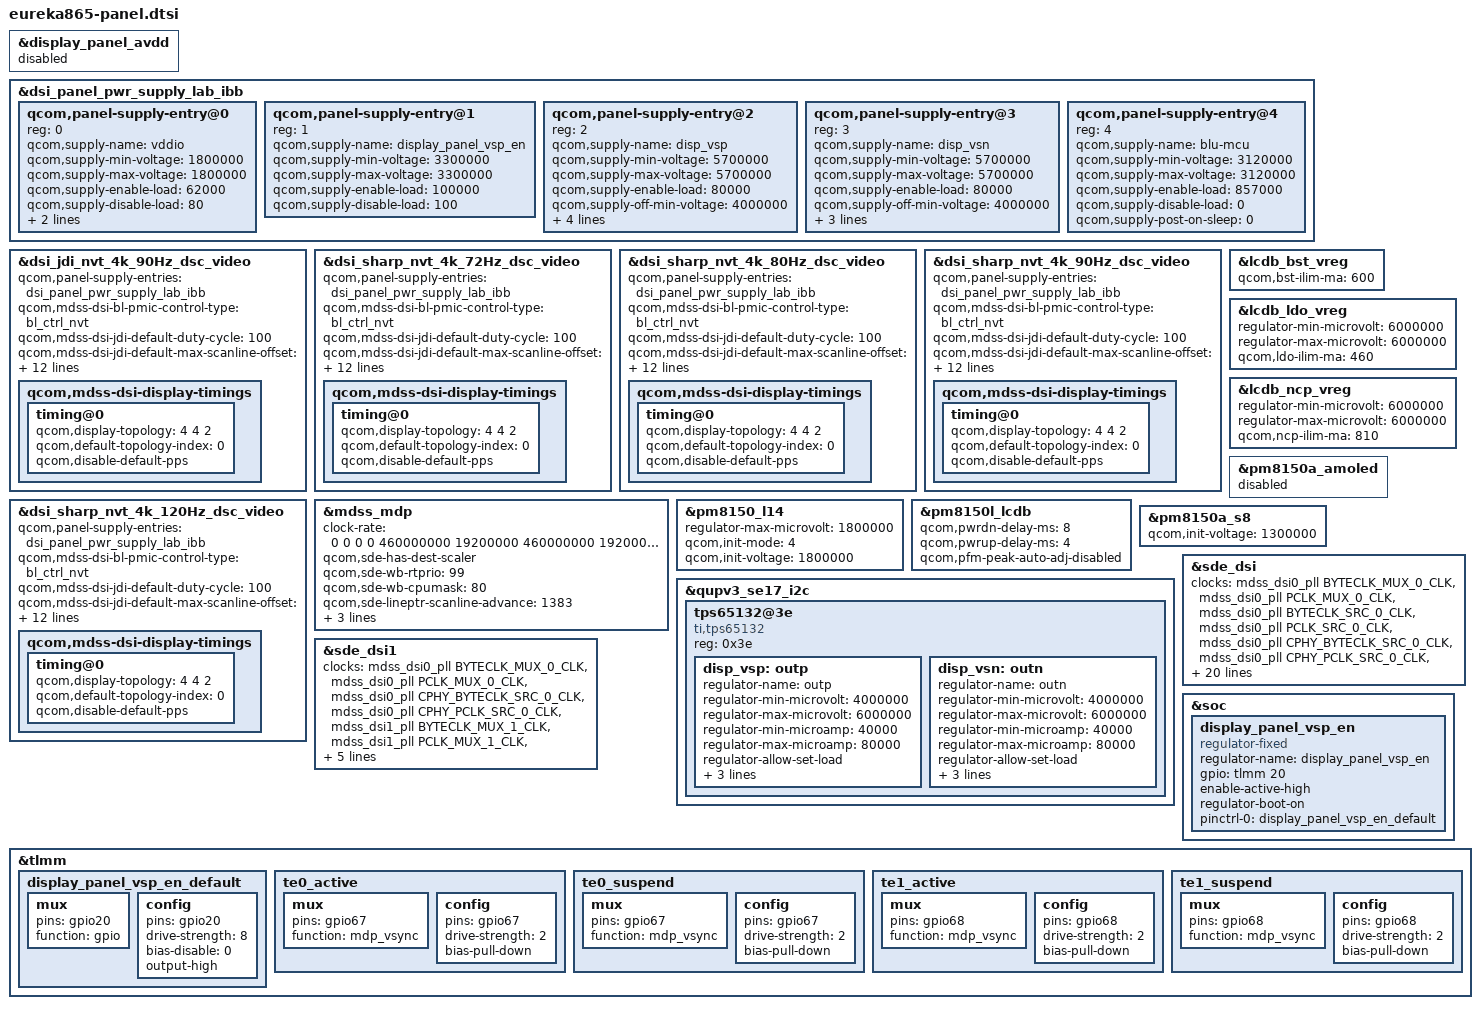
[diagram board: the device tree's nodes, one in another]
// SPDX-License-Identifier: GPL-2.0

#include "eureka865-dsi-panel-sharp-nvt-dsc-4k-72hz-video.dtsi"
#include "eureka865-dsi-panel-sharp-nvt-dsc-4k-80hz-video.dtsi"
#include "eureka865-dsi-panel-sharp-nvt-dsc-4k-90hz-video.dtsi"
#include "eureka865-dsi-panel-sharp-nvt-dsc-4k-120hz-video.dtsi"
#include "eureka865-dsi-panel-jdi-nvt-dsc-4k-90hz-video.dtsi"

&display_panel_avdd {
	status = "disabled";
};

&dsi_panel_pwr_supply_lab_ibb {
	qcom,panel-supply-entry@0 {
		reg = <0>;
		qcom,supply-name = "vddio";
		qcom,supply-min-voltage = <1800000>;
		qcom,supply-max-voltage = <1800000>;
		qcom,supply-enable-load = <62000>;
		qcom,supply-disable-load = <80>;
		qcom,supply-post-on-sleep = <20>;
		qcom,supply-pre-off-sleep = <15>;
	};

	qcom,panel-supply-entry@1 {
		reg = <1>;
		qcom,supply-name = "display_panel_vsp_en";
		qcom,supply-min-voltage = <3300000>;
		qcom,supply-max-voltage = <3300000>;
		qcom,supply-enable-load = <100000>;
		qcom,supply-disable-load = <100>;
	};

	qcom,panel-supply-entry@2 {
		reg = <2>;
		qcom,supply-name = "disp_vsp";
		qcom,supply-min-voltage = <5700000>;
		qcom,supply-max-voltage = <5700000>;
		qcom,supply-enable-load = <80000>;
		qcom,supply-off-min-voltage = <4000000>;
		qcom,supply-disable-load = <0>;
		qcom,supply-post-on-sleep = <20>;
		qcom,supply-pre-on-sleep = <10>;
		qcom,supply-pre-off-sleep = <10>;
	};

	qcom,panel-supply-entry@3 {
		reg = <3>;
		qcom,supply-name = "disp_vsn";
		qcom,supply-min-voltage = <5700000>;
		qcom,supply-max-voltage = <5700000>;
		qcom,supply-enable-load = <80000>;
		qcom,supply-off-min-voltage = <4000000>;
		qcom,supply-disable-load = <0>;
		qcom,supply-post-on-sleep = <0>;
		qcom,supply-pre-on-sleep = <10>;
	};

	qcom,panel-supply-entry@4 {
		reg = <4>;
		qcom,supply-name = "blu-mcu";
		qcom,supply-min-voltage = <3120000>;
		qcom,supply-max-voltage = <3120000>;
		qcom,supply-enable-load = <857000>;
		qcom,supply-disable-load = <0>;
		qcom,supply-post-on-sleep = <0>;
	};
};

&dsi_jdi_nvt_4k_90Hz_dsc_video {
	qcom,panel-supply-entries = <&dsi_panel_pwr_supply_lab_ibb>;
	qcom,mdss-dsi-bl-pmic-control-type = "bl_ctrl_nvt";
	qcom,mdss-dsi-jdi-default-duty-cycle = <100>; /* 10% duty */
	qcom,mdss-dsi-jdi-default-max-scanline-offset = <2036>;
	qcom,mdss-dsi-bl-min-level = <800>;
	qcom,mdss-dsi-bl-max-level = <1200>;
	qcom,platform-reset-gpio = <&tlmm 91 0>;
	qcom,panel-sec-reset-gpio = <&tlmm 49 0>;
	qcom,mdss-dsi-reset-off-delay = <30>;
	qcom,mdss-dsi-t-clk-post = <0x0F>;
	qcom,mdss-dsi-t-clk-pre = <0x1F>;
	qcom,mdss-dsi-qsync-min-refresh-rate = <60>;
	qcom,dsi-select-clocks = "mux_byte_clk0", "mux_pixel_clk0",
				"cphy_byte_clk0", "cphy_pixel_clk0";
	qcom,mdss-dsi-display-timings {
		timing@0{
			qcom,display-topology = <4 4 2>;
			qcom,default-topology-index = <0>;
			qcom,disable-default-pps;
		};
	};
};

&dsi_sharp_nvt_4k_72Hz_dsc_video {
	qcom,panel-supply-entries = <&dsi_panel_pwr_supply_lab_ibb>;
	qcom,mdss-dsi-bl-pmic-control-type = "bl_ctrl_nvt";
	qcom,mdss-dsi-jdi-default-duty-cycle = <100>; /* 10% duty */
	qcom,mdss-dsi-jdi-default-max-scanline-offset = <2036>;
	qcom,mdss-dsi-bl-min-level = <800>;
	qcom,mdss-dsi-bl-max-level = <1200>;
	qcom,platform-reset-gpio = <&tlmm 91 0>;
	qcom,panel-sec-reset-gpio = <&tlmm 49 0>;
	qcom,mdss-dsi-reset-off-delay = <30>;
	qcom,mdss-dsi-t-clk-post = <0x0F>;
	qcom,mdss-dsi-t-clk-pre = <0x1F>;
	qcom,mdss-dsi-qsync-min-refresh-rate = <60>;
	qcom,dsi-select-clocks = "mux_byte_clk0", "mux_pixel_clk0",
				"cphy_byte_clk0", "cphy_pixel_clk0";
	qcom,mdss-dsi-display-timings {
		timing@0{
			qcom,display-topology = <4 4 2>;
			qcom,default-topology-index = <0>;
			qcom,disable-default-pps;
		};
	};
};


&dsi_sharp_nvt_4k_80Hz_dsc_video {
	qcom,panel-supply-entries = <&dsi_panel_pwr_supply_lab_ibb>;
	qcom,mdss-dsi-bl-pmic-control-type = "bl_ctrl_nvt";
	qcom,mdss-dsi-jdi-default-duty-cycle = <100>; /* 10% duty */
	qcom,mdss-dsi-jdi-default-max-scanline-offset = <2036>;
	qcom,mdss-dsi-bl-min-level = <800>;
	qcom,mdss-dsi-bl-max-level = <1200>;
	qcom,platform-reset-gpio = <&tlmm 91 0>;
	qcom,panel-sec-reset-gpio = <&tlmm 49 0>;
	qcom,mdss-dsi-reset-off-delay = <30>;
	qcom,mdss-dsi-t-clk-post = <0x0F>;
	qcom,mdss-dsi-t-clk-pre = <0x1F>;
	qcom,mdss-dsi-qsync-min-refresh-rate = <60>;
	qcom,dsi-select-clocks = "mux_byte_clk0", "mux_pixel_clk0",
				"cphy_byte_clk0", "cphy_pixel_clk0";
	qcom,mdss-dsi-display-timings {
		timing@0{
			qcom,display-topology = <4 4 2>;
			qcom,default-topology-index = <0>;
			qcom,disable-default-pps;
		};
	};
};

&dsi_sharp_nvt_4k_90Hz_dsc_video {
	qcom,panel-supply-entries = <&dsi_panel_pwr_supply_lab_ibb>;
	qcom,mdss-dsi-bl-pmic-control-type = "bl_ctrl_nvt";
	qcom,mdss-dsi-jdi-default-duty-cycle = <100>; /* 10% duty */
	qcom,mdss-dsi-jdi-default-max-scanline-offset = <2036>;
	qcom,mdss-dsi-bl-min-level = <800>;
	qcom,mdss-dsi-bl-max-level = <1200>;
	qcom,platform-reset-gpio = <&tlmm 91 0>;
	qcom,panel-sec-reset-gpio = <&tlmm 49 0>;
	qcom,mdss-dsi-reset-off-delay = <30>;
	qcom,mdss-dsi-t-clk-post = <0x0F>;
	qcom,mdss-dsi-t-clk-pre = <0x1F>;
	qcom,mdss-dsi-qsync-min-refresh-rate = <60>;
	qcom,dsi-select-clocks = "mux_byte_clk0", "mux_pixel_clk0",
				"cphy_byte_clk0", "cphy_pixel_clk0";
	qcom,mdss-dsi-display-timings {
		timing@0{
			qcom,display-topology = <4 4 2>;
			qcom,default-topology-index = <0>;
			qcom,disable-default-pps;
		};
	};
};

&dsi_sharp_nvt_4k_120Hz_dsc_video {
	qcom,panel-supply-entries = <&dsi_panel_pwr_supply_lab_ibb>;
	qcom,mdss-dsi-bl-pmic-control-type = "bl_ctrl_nvt";
	qcom,mdss-dsi-jdi-default-duty-cycle = <100>; /* 10% duty */
	qcom,mdss-dsi-jdi-default-max-scanline-offset = <2036>;
	qcom,mdss-dsi-bl-min-level = <800>;
	qcom,mdss-dsi-bl-max-level = <1200>;
	qcom,platform-reset-gpio = <&tlmm 91 0>;
	qcom,panel-sec-reset-gpio = <&tlmm 49 0>;
	qcom,mdss-dsi-reset-off-delay = <30>;
	qcom,mdss-dsi-t-clk-post = <0x0F>;
	qcom,mdss-dsi-t-clk-pre = <0x1F>;
	qcom,mdss-dsi-qsync-min-refresh-rate = <60>;
	qcom,dsi-select-clocks = "mux_byte_clk0", "mux_pixel_clk0",
				"cphy_byte_clk0", "cphy_pixel_clk0";
	qcom,mdss-dsi-display-timings {
		timing@0{
			qcom,display-topology = <4 4 2>;
			qcom,default-topology-index = <0>;
			qcom,disable-default-pps;
		};
	};
};

&lcdb_bst_vreg {
	qcom,bst-ilim-ma = <600>;
};

&lcdb_ldo_vreg {
	regulator-min-microvolt = <6000000>;
	regulator-max-microvolt = <6000000>;
	qcom,ldo-ilim-ma = <460>;
};

&lcdb_ncp_vreg {
	regulator-min-microvolt = <6000000>;
	regulator-max-microvolt = <6000000>;
	qcom,ncp-ilim-ma = <810>;
};

&mdss_mdp {
	clock-rate = <0 0 0 0 460000000 19200000 460000000 19200000>;
	qcom,sde-has-dest-scaler;
	qcom,sde-wb-rtprio = <99>;
	qcom,sde-wb-cpumask = "80"; /* CPU7 */
	qcom,sde-lineptr-scanline-advance = <1383>;
	qcom,sde-wb-mild-tear-threshold = <700>;
	qcom,sde-wb-severe-tear-threshold = <500>;
	qcom,sde-wb-passes = <1>;
};

&pm8150a_amoled {
	status = "disabled";
};

&pm8150_l14 {
	regulator-max-microvolt = <1800000>;
	qcom,init-mode = <4>; /* RPMH_REGULATOR_MODE_HPM */
	qcom,init-voltage = <1800000>;
};

&pm8150l_lcdb {
	status = "ok";
	qcom,pwrdn-delay-ms = <8>;
	qcom,pwrup-delay-ms = <4>;
	qcom,pfm-peak-auto-adj-disabled;
};

&pm8150a_s8 {
	qcom,init-voltage = <1300000>;
};

&qupv3_se17_i2c {
	tps65132@3e {
		compatible = "ti,tps65132";
		reg = <0x3e>;

		disp_vsp: outp {
			regulator-name = "outp";
			regulator-min-microvolt = <4000000>;
			regulator-max-microvolt = <6000000>;
			regulator-min-microamp = <40000>;
			regulator-max-microamp = <80000>;
			regulator-allow-set-load;
			regulator-boot-on;
			enable-gpios = <&tlmm 20 0>;
			ti,active-discharge-time-us = <0>;
		};

		disp_vsn: outn {
			regulator-name = "outn";
			regulator-min-microvolt = <4000000>;
			regulator-max-microvolt = <6000000>;
			regulator-min-microamp = <40000>;
			regulator-max-microamp = <80000>;
			regulator-allow-set-load;
			regulator-boot-on;
			enable-gpios = <&tlmm 21 0>;
			ti,active-discharge-time-us = <0>;
		};
	};
};

&sde_dsi {
	clocks = <&mdss_dsi0_pll BYTECLK_MUX_0_CLK>,
		 <&mdss_dsi0_pll PCLK_MUX_0_CLK>,
		 <&mdss_dsi0_pll BYTECLK_SRC_0_CLK>,
		 <&mdss_dsi0_pll PCLK_SRC_0_CLK>,
		 <&mdss_dsi0_pll CPHY_BYTECLK_SRC_0_CLK>,
		 <&mdss_dsi0_pll CPHY_PCLK_SRC_0_CLK>,
		 <&mdss_dsi0_pll SHADOW_BYTECLK_SRC_0_CLK>,
		 <&mdss_dsi0_pll SHADOW_PCLK_SRC_0_CLK>,
		 <&mdss_dsi1_pll BYTECLK_MUX_1_CLK>,
		 <&mdss_dsi1_pll PCLK_MUX_1_CLK>,
		 <&mdss_dsi1_pll BYTECLK_SRC_1_CLK>,
		 <&mdss_dsi1_pll PCLK_SRC_1_CLK>,
		 <&mdss_dsi1_pll CPHY_BYTECLK_SRC_1_CLK>,
		 <&mdss_dsi1_pll CPHY_PCLK_SRC_1_CLK>,
		 <&mdss_dsi1_pll SHADOW_BYTECLK_SRC_1_CLK>,
		 <&mdss_dsi1_pll SHADOW_PCLK_SRC_1_CLK>;

	clock-names = "mux_byte_clk0", "mux_pixel_clk0",
			"src_byte_clk0", "src_pixel_clk0",
			"cphy_byte_clk0", "cphy_pixel_clk0",
			"shadow_byte_clk0", "shadow_pixel_clk0",
			"mux_byte_clk1", "mux_pixel_clk1",
			"src_byte_clk1", "src_pixel_clk1",
			"cphy_byte_clk1", "cphy_pixel_clk1",
			"shadow_byte_clk1", "shadow_pixel_clk1";

	avdd-supply = <>;
	lab-supply = <&lcdb_ldo_vreg>;
	ibb-supply = <&lcdb_ncp_vreg>;
	blu-mcu-supply = <&pm8150a_l11>;
	disp_vsn-supply = <&disp_vsn>;
	disp_vsp-supply = <&disp_vsp>;
	qcom,dsi-default-panel = <&dsi_sharp_nvt_4k_90Hz_dsc_video>;
	pinctrl-0 = <&te1_active>;
	pinctrl-1 = <&te1_suspend>;
};

&sde_dsi1 {
	clocks = <&mdss_dsi0_pll BYTECLK_MUX_0_CLK>,
		 <&mdss_dsi0_pll PCLK_MUX_0_CLK>,
		 <&mdss_dsi0_pll CPHY_BYTECLK_SRC_0_CLK>,
		 <&mdss_dsi0_pll CPHY_PCLK_SRC_0_CLK>,
		 <&mdss_dsi1_pll BYTECLK_MUX_1_CLK>,
		 <&mdss_dsi1_pll PCLK_MUX_1_CLK>,
		 <&mdss_dsi1_pll CPHY_BYTECLK_SRC_1_CLK>,
		 <&mdss_dsi1_pll CPHY_PCLK_SRC_1_CLK>;
	clock-names = "mux_byte_clk0", "mux_pixel_clk0",
		      "cphy_byte_clk0", "cphy_pixel_clk0",
		      "mux_byte_clk1", "mux_pixel_clk1",
		      "cphy_byte_clk1", "cphy_pixel_clk1";
	avdd-supply = <>;
	pinctrl-0 = <&te1_active>;
	pinctrl-1 = <&te1_suspend>;
};

&soc {
	display_panel_vsp_en: display_panel_vsp_en {
		compatible = "regulator-fixed";
		regulator-name = "display_panel_vsp_en";
		gpio = <&tlmm 20 0>;
		enable-active-high;
		regulator-boot-on;
		pinctrl-names = "default";
		pinctrl-0 = <&display_panel_vsp_en_default>;
	};
};

&tlmm {
	display_panel_vsp_en_default: display_panel_vsp_en_default {
		mux {
			pins = "gpio20";
			function = "gpio";
		};

		config {
			pins = "gpio20";
			drive-strength = <8>;
			bias-disable = <0>;
			output-high;
		};
	};

	te0_active: te0_active {
		mux {
			pins = "gpio67";
			function = "mdp_vsync";
		};

		config {
			pins = "gpio67";
			drive-strength = <2>;   /* 2 mA */
			bias-pull-down;         /* PULL DOWN */
		};
	};

	te0_suspend: te0_suspend {
		mux {
			pins = "gpio67";
			function = "mdp_vsync";
		};

		config {
			pins = "gpio67";
			drive-strength = <2>;   /* 2 mA */
			bias-pull-down;         /* PULL DOWN */
		};
	};

	te1_active: te1_active {
		mux {
			pins = "gpio68";
			function = "mdp_vsync";
		};

		config {
			pins = "gpio68";
			drive-strength = <2>;   /* 2 mA */
			bias-pull-down;         /* PULL DOWN */
		};
	};

	te1_suspend: te1_suspend {
		mux {
			pins = "gpio68";
			function = "mdp_vsync";
		};

		config {
			pins = "gpio68";
			drive-strength = <2>;   /* 2 mA */
			bias-pull-down;         /* PULL DOWN */
		};
	};
};
